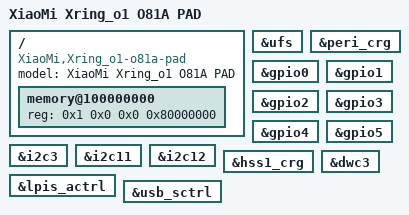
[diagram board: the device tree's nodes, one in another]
// SPDX-License-Identifier: (GPL-2.0+ OR MIT)
/*
 * Xiaomi Pad 7S Pro (violin / O81A / XRING O1) board device tree for UniXNU.
 *
 * Baselines:
 *   - MiCode/Xiaomi_Kernel_OpenSource branch violin-v-oss (99a9aff00a2856f065954672660bd0fe0ad0a064)
 *   - Live 2026-11-24 running-fdt.dtb (SHA-256 1c13390e68bee6d7eff86c7a4bd2ae29fd189971df0290cdc855e5c52c9ebbe8,
 *     Android 17 / Linux 6.18.21 / OS4.0.6.0.XOTCNXM) & /proc/iomem
 */

/dts-v1/;
/include/ "xring-o1.dtsi"

/ {
    model = "XiaoMi Xring_o1 O81A PAD";
    compatible = "XiaoMi,Xring_o1-o81a-pad", "XiaoMi,Franklin1-o81a-pad", "xring,o1";

    /*
     * Live 16 GiB 3-bank physical RAM reported by running-fdt.dtb:
     *   - Bank 0: 0x000000000..0x0bfffffff (3 GiB, fragmented by TEEOS/XHEE/ADSP/DPU reservations)
     *   - Bank 1: 0x100000000..0x3ffffffff (12 GiB; only 0x3ffffe000..0x3ffffffff border_prot_mem1 8 KiB reserved)
     *   - Bank 2: 0x800000000..0x83fffffff (1 GiB; upper 0x800e68000..0x83fffffff reserved)
     * Expose a clean contiguous 2 GiB window from Bank 1 matching payload.dram_size = "0x80000000"
     * until multi-bank UEFI memory handoff (DarwinBoot) is brought up on violin.
     */
    memory@100000000 {
        device_type = "memory";
        reg = <0x1 0x0 0x0 0x80000000>;
    };
};

/*
 * Stage-6B: Expose XRING O1 dwc_ufs@e1a40000 (/arm-io/ufshc) in violin.adt for
 * polled read-only XringUfs verification (xring-ufs-ro=1). Omit interrupts so
 * IODTMapInterruptsSharing does not chase FDT phandle (ADT expects AAPL,phandle).
 * Kept disabled in xring-o1.dtsi and absent in violin-qemu.dts for QEMU gate.
 */
&ufs {
    status = "okay";
    /delete-property/ interrupts;
};

/*
 * Stage-7F: Expose non-secure PERI_CRG, all 6 DW APB GPIO banks, and I2C3/I2C11
 * (dual KTZ8866A @ 0x11 backlight buses) for polled XringGpio/XringI2c/XringBacklight.
 * Delete FDT interrupts on polled nodes per PRJ-027.
 */
&peri_crg {
    status = "okay";
};

&gpio0 { status = "okay"; };
&gpio1 { status = "okay"; };
&gpio2 { status = "okay"; };
&gpio3 { status = "okay"; };
&gpio4 { status = "okay"; };
&gpio5 { status = "okay"; };

&i2c3 {
    status = "okay";
    /delete-property/ interrupts;
};

&i2c11 {
    status = "okay";
    /delete-property/ interrupts;
};

/*
 * Stage-7L: Expose non-secure USB2-HS Device Mode MMIO blocks (HSS1_CRG, LPIS_ACTRL,
 * USB_SCTRL, DWC_usb31 v2.00a, I2C12 for PTN3222 @ 0x4F) verified live 0-trap in Stage-7I.
 * Delete FDT interrupts on polled nodes per PRJ-027 until AppleUSBXDCI GIC bridge lands.
 */
&i2c12 {
    status = "okay";
    /delete-property/ interrupts;
};

&hss1_crg {
    status = "okay";
};

&lpis_actrl {
    status = "okay";
};

&usb_sctrl {
    status = "okay";
};

&dwc3 {
    status = "okay";
    /delete-property/ interrupts;
};

/*
 * Verified live 2026-11-24 FDT/iomem findings (OS4.0.6.0.XOTCNXM / Linux 6.18.21):
 *   - Reserved carveouts in Bank 0 include rsv_mem_zero@0 (0x0+0x200000), rsv_mem_dpu_logo@20000000
 *     (actual reg 0x24200000+0x10000000, shifted from 0x20000000 in 6.6.30 DTS), rsv_mem_teeos@35680000
 *     (0xc000000), rsv_mem_bl31@42880000 (0x400000), rsv_mem_log@43480000 (0xa00000),
 *     rsv_mem_xhee@70010000 (0x4000000), rsv_mem_ufs_param@70001000 (0x1000), rsv_mem_pstore@a0000000 (0x100000),
 *     rsv_mem_sec_region@bfffe000 (0x2000); Bank 1 tail border_prot_mem1@3ffffe000 (0x2000).
 *   - Console UART: live FDT enables dwuart3@ec118000 (SPI 144) and disables dwuart6@ec11a000 (SPI 146).
 *   - Display/input/wireless: 3200x2136@144Hz DSI panel, KTZ8866A backlight, NVT_xiaomi_touch_TC on
 *     spi@e1507000, nanosic@4c on i2c@ec10a000, MediaTek mt663x Wi-Fi/BT on pcie@ce400000.
 */
